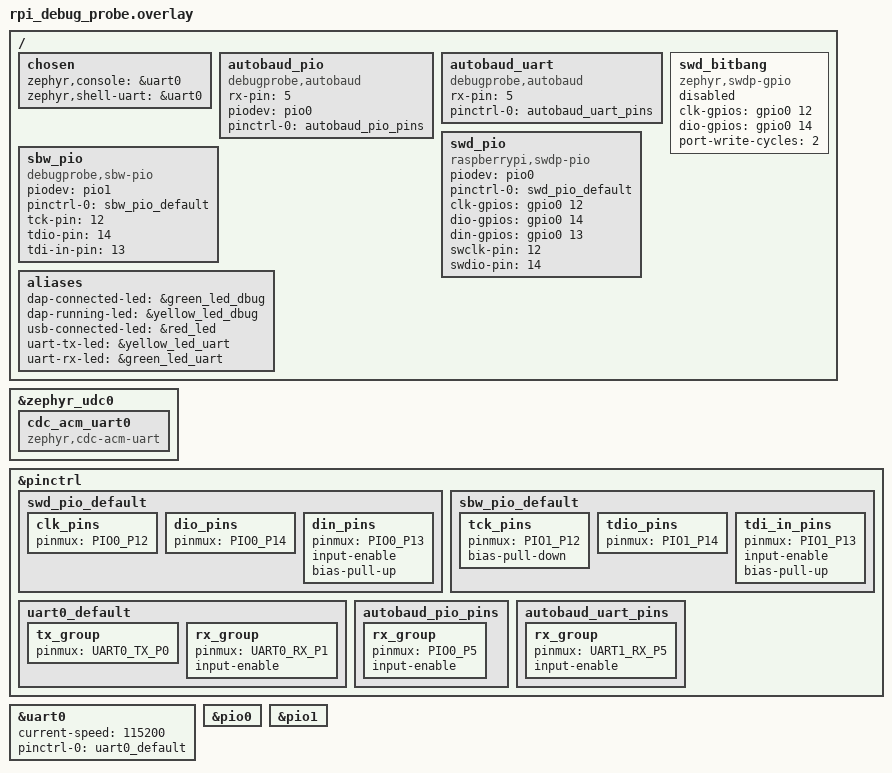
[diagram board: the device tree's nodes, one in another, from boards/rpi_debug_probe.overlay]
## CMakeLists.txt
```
cmake_minimum_required(VERSION 3.20.0)

# Register this repo as a Zephyr module (see zephyr/module.yml) so the
# out-of-tree PIO drivers in drivers/ (dp_pio and sbw_pio) are processed during Zephyr's
# module loop. That runs before Zephyr captures ZEPHYR_LIBS and builds the
# whole-archive link group; an app-local add_subdirectory() would register the
# driver too late, so their DEVICE_DT_INST_DEFINE device objects would be dropped
# and DEVICE_DT_GET(swd_pio) would fail to link. Must precede find_package().
list(APPEND EXTRA_ZEPHYR_MODULES ${CMAKE_CURRENT_SOURCE_DIR})

find_package(Zephyr REQUIRED HINTS $ENV{ZEPHYR_BASE})
project(debugprobe_zephyr LANGUAGES C CXX)

add_subdirectory(lib/dap)

target_sources(app PRIVATE
  src/main.cpp
  src/usb/usb_device.cpp
  src/usb/dap_class.cpp
  src/usb/msosv2.cpp
  src/dap/dap_backend.cpp
  src/leds.cpp
  src/pin_owner.cpp
  src/uart_bridge.cpp
  src/autobaud/autobaud.cpp
  src/autobaud/estimator.cpp
)

# The swdp_api adapter (and its C shim over the non-C++-clean swdp.h) is only
# needed for the real SWD backends; the NULL bring-up build excludes it.
if(NOT CONFIG_PROBE_SWD_NULL)
  target_sources(app PRIVATE
    src/dap/swdp_driver.cpp
    src/dap/swdp_shim.c
  )
endif()

# MSP430 Spy-Bi-Wire programming (vendor command 0x90): glue between the PIO
# driver in drivers/sbw_pio/, lib/msp430 and the DAP engine.
if(CONFIG_PROBE_MSP430_SBW)
  add_subdirectory(lib/msp430)
  target_sources(app PRIVATE
    src/msp430/pio_sbw_port.cpp
    src/msp430/msp430_backend.cpp
  )
  target_include_directories(app PRIVATE drivers/sbw_pio)
  target_link_libraries(app PRIVATE msp430)
endif()

target_include_directories(app PRIVATE src)
# The autobaud module (src/autobaud/autobaud.cpp) includes the generated
# autobaud_pio.h (PIO opcodes), which lives alongside the out-of-tree PIO
# driver in drivers/dp_pio/.
target_include_directories(app PRIVATE drivers/dp_pio)
target_link_libraries(app PRIVATE dap)
```

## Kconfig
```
mainmenu "debugprobe-zephyr"

config PROBE_PRODUCT_STRING
	string "USB product string"
	default "Debug Probe (CMSIS-DAP)" if BOARD_RPI_DEBUG_PROBE
	default "Debugprobe on Pico (CMSIS-DAP)" if BOARD_RPI_PICO || BOARD_RPI_PICO2
	default "Debugprobe (CMSIS-DAP)"

choice PROBE_SWD_BACKEND
	prompt "SWD driver backend"
	default PROBE_SWD_BITBANG
	help
	  Which SWD port driver backs the DAP engine.

config PROBE_SWD_NULL
	bool "Null (no SWD; bring-up only)"

config PROBE_SWD_BITBANG
	bool "Zephyr GPIO bitbang (zephyr,swdp-gpio)"

config PROBE_SWD_PIO
	bool "PIO-accelerated (raspberrypi,swdp-pio)"

endchoice

config PROBE_MSP430_SBW
	bool "MSP430 Spy-Bi-Wire programming and debugging (vendor command 0x90)"
	default y
	depends on PROBE_SWD_PIO && PIO_RPI_PICO && DT_HAS_DEBUGPROBE_SBW_PIO_ENABLED
	select SBW_PIO
	help
	  Program and debug MSP430 CPUXv2 flash devices (MSP430F5529) over
	  Spy-Bi-Wire, using the SWD pins. Adds a CMSIS-DAP vendor command; the
	  USB descriptors do not change. See docs/MSP430_SBW.md and
	  docs/MSP430_DEBUG.md.

# The SBW vendor command runs on the USB device thread and nests deeper than
# the SWD path (engine -> Session -> Debugger -> Cpuxv2/SbwTap -> port -> PIO
# driver). Zephyr's default of 1024 bytes leaves no margin for it. Static worst
# case of the debug paths, measured with -fstack-usage and the call graph on
# 2026-11-13: 1312 of 2048 bytes on the RP2040 boards (rpi_pico2: 1164), so
# 2048 is kept.
config USBD_THREAD_STACK_SIZE
	default 2048 if PROBE_MSP430_SBW

# The out-of-tree PIO driver Kconfigs (drivers/Kconfig, which pulls in dp_pio
# and sbw_pio) are sourced via the Zephyr module mechanism (zephyr/module.yml
# -> build.kconfig), not rsource'd here, so they are registered alongside the
# drivers' CMakeLists in the module loop. Sourcing them both ways would
# redefine SWDP_PIO.

source "Kconfig.zephyr"
```

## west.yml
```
manifest:
  remotes:
    - name: zephyrproject-rtos
      url-base: https://github.com/zephyrproject-rtos

  projects:
    - name: zephyr
      remote: zephyrproject-rtos
      revision: v4.4.0
      import:
        name-allowlist:
          - cmsis_6
          - hal_rpi_pico

  self:
    path: debugprobe-zephyr
```

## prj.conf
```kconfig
CONFIG_CPP=y
CONFIG_STD_CPP20=y
# GLIBCXX_LIBCPP (full libstdc++) depends on NEWLIB_LIBC || PICOLIBC;
# the gnuarmemb toolchain only provides newlib, so select it explicitly.
CONFIG_GLIBCXX_LIBCPP=y
CONFIG_NEWLIB_LIBC=y
CONFIG_LOG=y
CONFIG_USB_DEVICE_STACK_NEXT=y
CONFIG_USBD_CDC_ACM_CLASS=y
CONFIG_SERIAL=y
CONFIG_UART_LINE_CTRL=y
# CDC-ACM <-> target uart1 bridge is now a custom C++ UartBridge
# (src/uart_bridge.cpp), replacing the closed zephyr,uart-bridge so phase 4b
# can tap byte flow (activity LEDs) and intercept MAGIC_BAUD (autobaud). The
# bridge is interrupt-driven and ring-buffered, so it needs these explicitly
# (UART_INTERRUPT_DRIVEN was previously auto-selected by UART_BRIDGE):
CONFIG_UART_INTERRUPT_DRIVEN=y
CONFIG_RING_BUFFER=y
# Autobaud (src/autobaud/autobaud.cpp) uses a k_event to start/stop its
# capture thread, and uart_configure() to apply the detected baud at runtime.
CONFIG_EVENTS=y
CONFIG_UART_USE_RUNTIME_CONFIGURE=y
CONFIG_HWINFO=y
CONFIG_GPIO=y
CONFIG_DP_DRIVER=y
# Default SWD backend: PIO-accelerated (raspberrypi,swdp-pio). Flips the
# Kconfig choice default (BITBANG). The overlays default swd_pio=okay /
# swd_bitbang=disabled to match; switching to bitbang requires flipping both.
CONFIG_PROBE_SWD_PIO=y
# SWD block DMA (drivers/dp_pio): Zephyr DMA controller, not the raw SDK.
CONFIG_DMA=y
CONFIG_DMA_RPI_PICO=y
```

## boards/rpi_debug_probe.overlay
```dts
#include <zephyr/dt-bindings/pinctrl/rpi-pico-rp2040-pinctrl.h>

&zephyr_udc0 {
	cdc_acm_uart0: cdc_acm_uart0 {
		compatible = "zephyr,cdc-acm-uart";
	};
};

/* Route the Debug Probe's PIO SWD pins to PIO0 (the Zephyr way, via pinctrl).
 * SWCLK=GP12 (output), SWDIO=GP14 (output only -- the probe has a separate
 * input), SWDI=GP13 (the read pin: input-enable + pull-up).
 */
&pinctrl {
	swd_pio_default: swd_pio_default {
		clk_pins {
			pinmux = <PIO0_P12>;
		};
		dio_pins {
			pinmux = <PIO0_P14>;
		};
		din_pins {
			pinmux = <PIO0_P13>;
			input-enable;
			bias-pull-up;
		};
	};

	/* MSP430 Spy-Bi-Wire on the SWD pins, routed to PIO1: SBWTCK=GP12,
	 * SBWTDIO output=GP14, SBWTDIO input=GP13. */
	sbw_pio_default: sbw_pio_default {
		tck_pins {
			pinmux = <PIO1_P12>;
			bias-pull-down;
		};
		tdio_pins {
			pinmux = <PIO1_P14>;
		};
		tdi_in_pins {
			pinmux = <PIO1_P13>;
			input-enable;
			bias-pull-up;
		};
	};

	/* Console UART (uart0): TX=GP0, RX=GP1. The board defaults the console
	 * to uart1, but uart1 is the bridge target here, so the console moves to
	 * uart0 (chosen below) and needs its own pinctrl (the board DTS only
	 * defines uart1_default).
	 */
	uart0_default: uart0_default {
		tx_group {
			pinmux = <UART0_TX_P0>;
		};
		rx_group {
			pinmux = <UART0_RX_P1>;
			input-enable;
		};
	};

	/* Autobaud pin-handoff states for uart1 RX (GP5, same as the Picos). Two
	 * single-state dev-configs (the robust two-node approach): while
	 * measuring, route GP5 to PIO0 so the frequency-counter SM sees the
	 * edges; on stop, route it back to UART1 so the bridge's UART RX works
	 * again. Both keep input-enable so the pad samples the incoming line. */
	autobaud_pio_pins: autobaud_pio_pins {
		rx_group {
			pinmux = <PIO0_P5>;
			input-enable;
		};
	};
	autobaud_uart_pins: autobaud_uart_pins {
		rx_group {
			pinmux = <UART1_RX_P5>;
			input-enable;
		};
	};
};

/* Move the console/shell off uart1 (the board DTS chose uart1) so the bridge
 * owns uart1 exclusively, and enable uart0 as the console UART.
 */
&uart0 {
	status = "okay";
	current-speed = <115200>;
	pinctrl-0 = <&uart0_default>;
	pinctrl-names = "default";
};

/* Enable PIO0 so the misc PIO HAL (PIO_RPI_PICO) builds, which the dp_pio
 * driver compiles against, and so the raspberrypi,swdp-pio instance can run.
 */
&pio0 {
	status = "okay";
};

/* PIO1 hosts the SBW program: PIO0's instruction memory is shared by the SWD
 * and autobaud programs. */
&pio1 {
	status = "okay";
};

/ {
	/* uart1 is already enabled (status=okay, uart1_default pinctrl) in the
	 * board DTS and was the console -- move the console/shell to uart0 so the
	 * CDC-ACM <-> uart1 bridge owns uart1.
	 */
	chosen {
		zephyr,console = &uart0;
		zephyr,shell-uart = &uart0;
	};

	/* CDC-ACM (USB) <-> uart1 (target) bridge is now a custom C++ UartBridge
	 * (src/uart_bridge.cpp) that binds cdc_acm_uart0 and uart1 (already okay
	 * in the board DTS) directly, so there is no zephyr,uart-bridge DT node
	 * here anymore.
	 */

	/* Autobaud pin-handoff anchors (compatible debugprobe,autobaud). The
	 * autobaud module (src/autobaud/autobaud.cpp) references these two nodes
	 * via DT_NODELABEL to obtain the two single-state pinctrl dev-configs:
	 * autobaud_pio routes uart1 RX (GP5) to PIO0 while measuring;
	 * autobaud_uart routes it back to UART1 on stop. rx-pin carries the RX
	 * GPIO number for the PIO SM config. No driver binds these; the binding
	 * exists only for the pinctrl + rx-pin DT codegen. */
	autobaud_pio: autobaud_pio {
		compatible = "debugprobe,autobaud";
		rx-pin = <5>;
		piodev = <&pio0>;
		pinctrl-0 = <&autobaud_pio_pins>;
		pinctrl-names = "default";
	};
	autobaud_uart: autobaud_uart {
		compatible = "debugprobe,autobaud";
		rx-pin = <5>;
		pinctrl-0 = <&autobaud_uart_pins>;
		pinctrl-names = "default";
	};

	/* The real Raspberry Pi Debug Probe (PROBE_IO_SWDI, per
	 * board_debug_probe_config.h): SWCLK=GP12, SWDIO output=GP14, separate
	 * SWDI input=GP13, no OEn, no nRESET pin. The PIO node carries a
	 * din-gpios for the separate input (driver use_swdi axis, still
	 * probe.pio). Exactly one backend is enabled: PIO is the default
	 * (CONFIG_PROBE_SWD_PIO=y); to use bitbang, flip both the Kconfig
	 * choice and these two status values.
	 */
	swd_bitbang: swd_bitbang {
		compatible = "zephyr,swdp-gpio";
		clk-gpios = <&gpio0 12 GPIO_ACTIVE_HIGH>;
		dio-gpios = <&gpio0 14 (GPIO_PULL_UP | GPIO_ACTIVE_HIGH)>;
		port-write-cycles = <2>;
		status = "disabled";
	};

	swd_pio: swd_pio {
		compatible = "raspberrypi,swdp-pio";
		piodev = <&pio0>;
		pinctrl-0 = <&swd_pio_default>;
		pinctrl-names = "default";
		clk-gpios = <&gpio0 12 GPIO_ACTIVE_HIGH>;
		dio-gpios = <&gpio0 14 GPIO_ACTIVE_HIGH>;
		din-gpios = <&gpio0 13 GPIO_ACTIVE_HIGH>;
		swclk-pin = <12>;
		swdio-pin = <14>;
		status = "okay";
	};

	sbw_pio: sbw_pio {
		compatible = "debugprobe,sbw-pio";
		piodev = <&pio1>;
		pinctrl-0 = <&sbw_pio_default>;
		pinctrl-names = "default";
		tck-pin = <12>;
		tdio-pin = <14>;
		tdi-in-pin = <13>;
		status = "okay";
	};

	/* Status LEDs (gpio-leds nodes in the board DTS), matching the original
	 * debug-probe mapping: DAP_CONNECTED=GP15 (green_led_dbug),
	 * DAP_RUNNING=GP16 (yellow_led_dbug), USB=GP2 (red_led).
	 */
	aliases {
		dap-connected-led = &green_led_dbug;
		dap-running-led = &yellow_led_dbug;
		usb-connected-led = &red_led;
		uart-tx-led = &yellow_led_uart;
		uart-rx-led = &green_led_uart;
	};
};
```

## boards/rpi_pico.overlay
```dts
#include <zephyr/dt-bindings/pinctrl/rpi-pico-rp2040-pinctrl.h>

&zephyr_udc0 {
	cdc_acm_uart0: cdc_acm_uart0 {
		compatible = "zephyr,cdc-acm-uart";
	};
};

/* Route the PIO SWD pins to the PIO0 function (the Zephyr way, via pinctrl).
 * SWCLK=GP2 (PIO output), SWDIO=GP3 (shared in/out: input-enable so `in pins`
 * can sample it, pull-up for the idle-high SWD bus).
 */
&pinctrl {
	swd_pio_default: swd_pio_default {
		clk_pins {
			pinmux = <PIO0_P2>;
		};
		dio_pins {
			pinmux = <PIO0_P3>;
			input-enable;
			bias-pull-up;
		};
	};

	/* MSP430 Spy-Bi-Wire on the SWD pins, routed to PIO1: SBWTCK=GP2 (target
	 * TEST), SBWTDIO=GP3 (target RST). The pulls define the idle state:
	 * pull-up on SBWTDIO so the probe does not fight the target's RST
	 * pull-up, pull-down on SBWTCK (TEST low = SBW logic off). */
	sbw_pio_default: sbw_pio_default {
		tck_pins {
			pinmux = <PIO1_P2>;
			bias-pull-down;
		};
		tdio_pins {
			pinmux = <PIO1_P3>;
			input-enable;
			bias-pull-up;
		};
	};

	/* Target UART (uart1): TX=GP4, RX=GP5 -- the CDC-ACM bridge endpoint. */
	uart1_default: uart1_default {
		tx_group {
			pinmux = <UART1_TX_P4>;
		};
		rx_group {
			pinmux = <UART1_RX_P5>;
			input-enable;
		};
	};

	/* Autobaud pin-handoff states for uart1 RX (GP5). Two single-state
	 * dev-configs (the robust two-node approach): while measuring, route GP5
	 * to PIO0 so the frequency-counter SM sees the edges; on stop, route it
	 * back to UART1 so the bridge's UART RX works again. Both keep
	 * input-enable so the pad samples the incoming line. */
	autobaud_pio_pins: autobaud_pio_pins {
		rx_group {
			pinmux = <PIO0_P5>;
			input-enable;
		};
	};
	autobaud_uart_pins: autobaud_uart_pins {
		rx_group {
			pinmux = <UART1_RX_P5>;
			input-enable;
		};
	};
};

/* Enable uart1 as the bridge's hardware side. The board defaults the console
 * to uart0 (GP0/GP1), so uart1 is free to be the target UART.
 */
&uart1 {
	status = "okay";
	current-speed = <115200>;
	pinctrl-0 = <&uart1_default>;
	pinctrl-names = "default";
};

/* Enable PIO0 so the misc PIO HAL (PIO_RPI_PICO) builds, which the dp_pio
 * driver compiles against, and so the raspberrypi,swdp-pio instance can run.
 */
&pio0 {
	status = "okay";
};

/* PIO1 hosts the SBW program: PIO0's instruction memory is shared by the SWD
 * and autobaud programs. */
&pio1 {
	status = "okay";
};

/ {
	/* CDC-ACM (USB) <-> uart1 (target) bridge is now a custom C++ UartBridge
	 * (src/uart_bridge.cpp) that binds cdc_acm_uart0 and uart1 directly, so
	 * there is no zephyr,uart-bridge DT node here anymore.
	 */

	/* Autobaud pin-handoff anchors (compatible debugprobe,autobaud). The
	 * autobaud module (src/autobaud/autobaud.cpp) references these two nodes
	 * via DT_NODELABEL to obtain the two single-state pinctrl dev-configs:
	 * autobaud_pio routes uart1 RX (GP5) to PIO0 while measuring;
	 * autobaud_uart routes it back to UART1 on stop. rx-pin carries the RX
	 * GPIO number for the PIO SM config. No driver binds these; the binding
	 * exists only for the pinctrl + rx-pin DT codegen. */
	autobaud_pio: autobaud_pio {
		compatible = "debugprobe,autobaud";
		rx-pin = <5>;
		piodev = <&pio0>;
		pinctrl-0 = <&autobaud_pio_pins>;
		pinctrl-names = "default";
	};
	autobaud_uart: autobaud_uart {
		compatible = "debugprobe,autobaud";
		rx-pin = <5>;
		pinctrl-0 = <&autobaud_uart_pins>;
		pinctrl-names = "default";
	};

	/* Two SWD backends share these pins (GP2=SWCLK, GP3=shared SWDIO,
	 * GP1=nRESET). Exactly one is enabled at a time: the PIO node is the
	 * default (CONFIG_PROBE_SWD_PIO=y); to use bitbang, flip both the
	 * Kconfig choice and these two status values.
	 */
	swd_bitbang: swd_bitbang {
		compatible = "zephyr,swdp-gpio";
		clk-gpios = <&gpio0 2 GPIO_ACTIVE_HIGH>;
		dio-gpios = <&gpio0 3 (GPIO_PULL_UP | GPIO_ACTIVE_HIGH)>;
		reset-gpios = <&gpio0 1 GPIO_ACTIVE_LOW>;
		port-write-cycles = <2>;
		status = "disabled";
	};

	swd_pio: swd_pio {
		compatible = "raspberrypi,swdp-pio";
		piodev = <&pio0>;
		pinctrl-0 = <&swd_pio_default>;
		pinctrl-names = "default";
		clk-gpios = <&gpio0 2 GPIO_ACTIVE_HIGH>;
		dio-gpios = <&gpio0 3 (GPIO_PULL_UP | GPIO_ACTIVE_HIGH)>;
		reset-gpios = <&gpio0 1 GPIO_ACTIVE_LOW>;
		swclk-pin = <2>;
		swdio-pin = <3>;
		status = "okay";
	};

	sbw_pio: sbw_pio {
		compatible = "debugprobe,sbw-pio";
		piodev = <&pio1>;
		pinctrl-0 = <&sbw_pio_default>;
		pinctrl-names = "default";
		tck-pin = <2>;
		tdio-pin = <3>;
		status = "okay";
	};

	/* Single onboard LED (led0 = GP25): use it as the USB-connected
	 * indicator. There are no separate DAP connect/run LEDs on this board,
	 * so those aliases are absent and their helpers no-op.
	 */
	aliases {
		usb-connected-led = &led0;
	};
};
```

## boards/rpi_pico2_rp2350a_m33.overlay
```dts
#include <zephyr/dt-bindings/pinctrl/rpi-pico-rp2350a-pinctrl.h>

&zephyr_udc0 {
	cdc_acm_uart0: cdc_acm_uart0 {
		compatible = "zephyr,cdc-acm-uart";
	};
};

/* Route the PIO SWD pins to the PIO0 function (the Zephyr way, via pinctrl).
 * SWCLK=GP2 (PIO output), SWDIO=GP3 (shared in/out: input-enable + pull-up).
 */
&pinctrl {
	swd_pio_default: swd_pio_default {
		clk_pins {
			pinmux = <PIO0_P2>;
		};
		dio_pins {
			pinmux = <PIO0_P3>;
			input-enable;
			bias-pull-up;
		};
	};

	/* MSP430 Spy-Bi-Wire on the SWD pins, routed to PIO1: SBWTCK=GP2 (target
	 * TEST), SBWTDIO=GP3 (target RST). The pulls define the idle state:
	 * pull-up on SBWTDIO so the probe does not fight the target's RST
	 * pull-up, pull-down on SBWTCK (TEST low = SBW logic off). */
	sbw_pio_default: sbw_pio_default {
		tck_pins {
			pinmux = <PIO1_P2>;
			bias-pull-down;
		};
		tdio_pins {
			pinmux = <PIO1_P3>;
			input-enable;
			bias-pull-up;
		};
	};

	/* Target UART (uart1): TX=GP4, RX=GP5 -- the CDC-ACM bridge endpoint. */
	uart1_default: uart1_default {
		tx_group {
			pinmux = <UART1_TX_P4>;
		};
		rx_group {
			pinmux = <UART1_RX_P5>;
			input-enable;
		};
	};

	/* Autobaud pin-handoff states for uart1 RX (GP5). Two single-state
	 * dev-configs (the robust two-node approach): while measuring, route GP5
	 * to PIO0 so the frequency-counter SM sees the edges; on stop, route it
	 * back to UART1 so the bridge's UART RX works again. Both keep
	 * input-enable so the pad samples the incoming line. */
	autobaud_pio_pins: autobaud_pio_pins {
		rx_group {
			pinmux = <PIO0_P5>;
			input-enable;
		};
	};
	autobaud_uart_pins: autobaud_uart_pins {
		rx_group {
			pinmux = <UART1_RX_P5>;
			input-enable;
		};
	};
};

/* Enable uart1 as the bridge's hardware side. The board defaults the console
 * to uart0 (GP0/GP1), so uart1 is free to be the target UART.
 */
&uart1 {
	status = "okay";
	current-speed = <115200>;
	pinctrl-0 = <&uart1_default>;
	pinctrl-names = "default";
};

/* Enable PIO0 so the misc PIO HAL (PIO_RPI_PICO) builds, which the dp_pio
 * driver compiles against, and so the raspberrypi,swdp-pio instance can run.
 */
&pio0 {
	status = "okay";
};

/* PIO1 hosts the SBW program: PIO0's instruction memory is shared by the SWD
 * and autobaud programs. */
&pio1 {
	status = "okay";
};

/ {
	/* CDC-ACM (USB) <-> uart1 (target) bridge is now a custom C++ UartBridge
	 * (src/uart_bridge.cpp) that binds cdc_acm_uart0 and uart1 directly, so
	 * there is no zephyr,uart-bridge DT node here anymore.
	 */

	/* Autobaud pin-handoff anchors (compatible debugprobe,autobaud). The
	 * autobaud module (src/autobaud/autobaud.cpp) references these two nodes
	 * via DT_NODELABEL to obtain the two single-state pinctrl dev-configs:
	 * autobaud_pio routes uart1 RX (GP5) to PIO0 while measuring;
	 * autobaud_uart routes it back to UART1 on stop. rx-pin carries the RX
	 * GPIO number for the PIO SM config. No driver binds these; the binding
	 * exists only for the pinctrl + rx-pin DT codegen. */
	autobaud_pio: autobaud_pio {
		compatible = "debugprobe,autobaud";
		rx-pin = <5>;
		piodev = <&pio0>;
		pinctrl-0 = <&autobaud_pio_pins>;
		pinctrl-names = "default";
	};
	autobaud_uart: autobaud_uart {
		compatible = "debugprobe,autobaud";
		rx-pin = <5>;
		pinctrl-0 = <&autobaud_uart_pins>;
		pinctrl-names = "default";
	};

	/* Two SWD backends share these pins (GP2=SWCLK, GP3=shared SWDIO,
	 * GP1=nRESET). Exactly one is enabled at a time: the PIO node is the
	 * default (CONFIG_PROBE_SWD_PIO=y); to use bitbang, flip both the
	 * Kconfig choice and these two status values.
	 */
	swd_bitbang: swd_bitbang {
		compatible = "zephyr,swdp-gpio";
		clk-gpios = <&gpio0 2 GPIO_ACTIVE_HIGH>;
		dio-gpios = <&gpio0 3 (GPIO_PULL_UP | GPIO_ACTIVE_HIGH)>;
		reset-gpios = <&gpio0 1 GPIO_ACTIVE_LOW>;
		port-write-cycles = <2>;
		status = "disabled";
	};

	swd_pio: swd_pio {
		compatible = "raspberrypi,swdp-pio";
		piodev = <&pio0>;
		pinctrl-0 = <&swd_pio_default>;
		pinctrl-names = "default";
		clk-gpios = <&gpio0 2 GPIO_ACTIVE_HIGH>;
		dio-gpios = <&gpio0 3 (GPIO_PULL_UP | GPIO_ACTIVE_HIGH)>;
		reset-gpios = <&gpio0 1 GPIO_ACTIVE_LOW>;
		swclk-pin = <2>;
		swdio-pin = <3>;
		status = "okay";
	};

	sbw_pio: sbw_pio {
		compatible = "debugprobe,sbw-pio";
		piodev = <&pio1>;
		pinctrl-0 = <&sbw_pio_default>;
		pinctrl-names = "default";
		tck-pin = <2>;
		tdio-pin = <3>;
		status = "okay";
	};

	/* Single onboard LED (led0): use it as the USB-connected indicator.
	 * No separate DAP connect/run LEDs on this board, so those aliases are
	 * absent and their helpers no-op.
	 */
	aliases {
		usb-connected-led = &led0;
	};
};
```

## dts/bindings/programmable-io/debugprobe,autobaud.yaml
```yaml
# Copyright The Zephyr Project Contributors
# SPDX-License-Identifier: Apache-2.0

description: |
  Autobaud pin-handoff anchor. Carries a single pinctrl state used by the
  autobaud module (src/autobaud/autobaud.cpp) to route uart1's RX pin either to
  PIO0 (while the frequency counter measures) or back to UART1 (on stop). No
  driver binds these nodes; the binding exists only so devicetree emits the
  pinctrl-0/pinctrl-names metadata and the rx-pin property.

compatible: "debugprobe,autobaud"

# pinctrl-device.yaml provides pinctrl-0/pinctrl-names codegen (the same include
# raspberrypi,swdp-pio uses to route pins to the PIO funcsel).
include: [base.yaml, pinctrl-device.yaml]

properties:
  rx-pin:
    type: int
    required: true
    description: uart1 RX GPIO number, passed to the PIO SM as in_pins/jmp_pin.

  piodev:
    type: phandle
    description: |
      The PIO instance (pio0) the autobaud frequency counter runs on. A phandle
      (not DT_NODELABEL(pio0)) so the reference survives the pico-sdk
      hardware/pio.h `#define pio0 pio0_hw` token collision.
```

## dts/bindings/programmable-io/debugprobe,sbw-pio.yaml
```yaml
# SPDX-License-Identifier: MIT

description: |
  PIO Spy-Bi-Wire transport for MSP430 targets. Shares the SWD pins: SBWTCK on
  the SWCLK pin (target TEST), SBWTDIO on the SWDIO pin (target RST). The
  pinctrl state routes the pins to this node's PIO instance and sets the idle
  pulls (pull-up on SBWTDIO, pull-down on SBWTCK).

compatible: "debugprobe,sbw-pio"

include: [base.yaml, pinctrl-device.yaml]

properties:
  piodev:
    type: phandle
    required: true
    description: |
      The PIO instance that runs the SBW program. A phandle (not a node label
      in C) because hardware/pio.h defines pio0/pio1 as macros.

  tck-pin:
    type: int
    required: true
    description: SBWTCK GPIO number (PIO side-set base).

  tdio-pin:
    type: int
    required: true
    description: SBWTDIO GPIO number (PIO out/set base, and input base by default).

  tdi-in-pin:
    type: int
    description: Separate SBWTDIO input GPIO, for boards with split in/out pins.
```

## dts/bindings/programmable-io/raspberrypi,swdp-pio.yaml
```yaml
# Copyright The Zephyr Project Contributors
# SPDX-License-Identifier: Apache-2.0

description: Raspberry Pi PIO-accelerated SWD port

compatible: "raspberrypi,swdp-pio"

# base.yaml: status/compatible/etc. pinctrl-device.yaml: pinctrl-0/pinctrl-names,
# used (the Zephyr way, as in raspberrypi,pico-uart-pio) to route SWCLK/SWDIO/SWDI
# to the PIO funcsel. swclk-pin/swdio-pin still give the PIO SM its side-set/out/in
# pin numbers; nRESET goes through reset-gpios.
include: [base.yaml, pinctrl-device.yaml]

properties:
  piodev:
    type: phandle
    required: true
    description: The PIO instance (pio0/pio1) hosting the SWD program.

  clk-gpios:
    type: phandle-array
    required: true
    description: SWCLK pin.

  dio-gpios:
    type: phandle-array
    required: true
    description: SWDIO pin (shared in/out on Pico; output on buffered probe).

  din-gpios:
    type: phandle-array
    description: Separate SWDIO input pin (buffered Debug Probe only).

  oen-gpios:
    type: phandle-array
    description: Output-enable pin for the level shifter (buffered probe only).

  reset-gpios:
    type: phandle-array
    description: Target nRESET pin (open-drain emulation).

  swclk-pin:
    type: int
    required: true
    description: SWCLK GPIO number (PIO side-set base).

  swdio-pin:
    type: int
    required: true
    description: SWDIO GPIO number (PIO out/in base).
```

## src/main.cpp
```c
#include <zephyr/kernel.h>
#include <zephyr/logging/log.h>

#include <array>
#include <span>

#include "usb/usb_device.hpp"
#include "uart_bridge.hpp"

#if defined(CONFIG_PROBE_MSP430_SBW)
#include "msp430/msp430_backend.hpp"
#endif

LOG_MODULE_REGISTER(main, LOG_LEVEL_INF);

namespace {

/* C++20 smoke check: if concepts + std::span compile, the toolchain and
 * Kconfig selections are correct.
 */
template <typename T>
concept ByteBuffer = requires(T t) {
	{ t.size() } -> std::convertible_to<size_t>;
	{ t.data() };
};

static_assert(ByteBuffer<std::array<uint8_t, 4>>);
static_assert(ByteBuffer<std::span<const uint8_t>>);

} // namespace

int main()
{
	LOG_INF("debugprobe-zephyr starting");

#if defined(CONFIG_PROBE_MSP430_SBW)
	/* MSP430 Spy-Bi-Wire: vendor command 0x90 on the DAP interface. */
	probe::msp430_backend::init();
#endif

	if (int err = probe::usb::init(); err != 0) {
		LOG_ERR("USB init failed: %d", err);
		return err;
	}

	/* Wire the CDC-ACM <-> uart1 data path (custom interrupt-driven bridge,
	 * replacing zephyr,uart-bridge). */
	probe::uart_bridge_init();

	/* USB runs on the usbd thread + controller IRQs; nothing for main to do. */
	return 0;
}
```

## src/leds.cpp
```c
#include "leds.hpp"

#include <zephyr/devicetree.h>
#include <zephyr/drivers/gpio.h>
#include <zephyr/kernel.h>

namespace probe {

namespace {

/* A LED is present only if the alias resolves to a gpios property. Each entry
 * is compiled out to an empty spec ({0}) when its alias is absent, and the
 * helpers no-op on a null port. */
#define LED_SPEC(alias) \
	GPIO_DT_SPEC_GET_OR(DT_ALIAS(alias), gpios, {0})

const struct gpio_dt_spec dap_connected = LED_SPEC(dap_connected_led);
const struct gpio_dt_spec dap_running = LED_SPEC(dap_running_led);
const struct gpio_dt_spec usb_connected = LED_SPEC(usb_connected_led);
const struct gpio_dt_spec uart_tx_led = LED_SPEC(uart_tx_led);
const struct gpio_dt_spec uart_rx_led = LED_SPEC(uart_rx_led);

void led_configure(const struct gpio_dt_spec *led)
{
	if (led->port != nullptr && gpio_is_ready_dt(led)) {
		gpio_pin_configure_dt(led, GPIO_OUTPUT_INACTIVE);
	}
}

void led_set(const struct gpio_dt_spec *led, bool on)
{
	if (led->port != nullptr && gpio_is_ready_dt(led)) {
		gpio_pin_set_dt(led, on ? 1 : 0);
	}
}

void tx_off(struct k_timer *) { led_set(&uart_tx_led, false); }
void rx_off(struct k_timer *) { led_set(&uart_rx_led, false); }
K_TIMER_DEFINE(tx_timer, tx_off, nullptr);
K_TIMER_DEFINE(rx_timer, rx_off, nullptr);
constexpr k_timeout_t kDebounce = K_MSEC(40);

struct LedInit {
	LedInit()
	{
		led_configure(&dap_connected);
		led_configure(&dap_running);
		led_configure(&usb_connected);
		led_configure(&uart_tx_led);
		led_configure(&uart_rx_led);
	}
};
const LedInit led_init;

} // namespace

void LedHostStatus::connected(bool on)
{
	led_set(&dap_connected, on);
}

void LedHostStatus::running(bool on)
{
	led_set(&dap_running, on);
}

void leds_usb_connected(bool on)
{
	led_set(&usb_connected, on);
}

void leds_uart_tx_activity()
{
	led_set(&uart_tx_led, true);
	k_timer_start(&tx_timer, kDebounce, K_NO_WAIT);
}

void leds_uart_rx_activity()
{
	led_set(&uart_rx_led, true);
	k_timer_start(&rx_timer, kDebounce, K_NO_WAIT);
}

} // namespace probe
```

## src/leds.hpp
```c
#pragma once
/* Drives the probe's status LEDs from the DAP engine's HostStatus.
 * Uses devicetree aliases (dap-connected-led, dap-running-led,
 * usb-connected-led); any alias that is absent on a board is a no-op.
 */
#include "dap/interfaces.hpp"

namespace probe {

class LedHostStatus final : public dap::HostStatus {
public:
	void connected(bool on) override;   /* DAP target connected (HostStatus type 0) */
	void running(bool on) override;     /* DAP target running (HostStatus type 1) */
};

/* Turn the USB-connected indicator on once the USB device is configured. */
void leds_usb_connected(bool on);

/* UART bridge activity: call on each byte; the LED lights and auto-clears
 * ~40 ms after the last byte (debounce). No-op if the alias is absent. */
void leds_uart_tx_activity();
void leds_uart_rx_activity();

} // namespace probe
```

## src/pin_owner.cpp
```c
#include "pin_owner.hpp"

namespace probe::pin_owner {

namespace {

enum class Owner { None, Swd, Sbw };

Owner g_owner = Owner::None;
void (*g_force_close)() = nullptr;
void (*g_idle)() = nullptr;

} // namespace

void swd_connect()
{
	if (g_owner == Owner::Sbw && g_force_close != nullptr) {
		g_force_close(); /* releases the pins through sbw_release() */
	}
	g_owner = Owner::Swd;
}

void swd_disconnect()
{
	if (g_owner == Owner::Swd) {
		g_owner = Owner::None;
		if (g_idle != nullptr) {
			g_idle(); /* the SWD driver leaves the pins driven */
		}
	}
}

bool sbw_claim()
{
	if (g_owner == Owner::Swd) {
		return false;
	}
	g_owner = Owner::Sbw;
	return true;
}

void sbw_release()
{
	if (g_owner == Owner::Sbw) {
		g_owner = Owner::None;
	}
}

bool sbw_owns()
{
	return g_owner == Owner::Sbw;
}

void set_sbw_force_close(void (*hook)())
{
	g_force_close = hook;
}

void set_idle_hook(void (*hook)())
{
	g_idle = hook;
}

} // namespace probe::pin_owner
```

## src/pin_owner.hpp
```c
#pragma once
/* Who drives the two debug pins: the SWD port (PIO0) or the SBW port (PIO1).
 * Pure C++ (host-tested). Every call comes from the DAP request thread, so
 * there is no locking.
 */
namespace probe::pin_owner {

/* SWD is taking the pins. An open SBW session is force-closed first, so a
 * crashed SBW tool cannot lock out an SWD debugger. */
void swd_connect();
void swd_disconnect();

/* SBW asks for the pins. Refused while SWD is connected. */
bool sbw_claim();
void sbw_release();
/* True while SBW holds the pins. */
bool sbw_owns();

/* Hook that closes an open SBW session; installed by the MSP430 backend. */
void set_sbw_force_close(void (*hook)());
/* Hook that returns the pins to their idle state (high-impedance, idle pulls)
 * after SWD lets go of them; installed by the MSP430 backend. */
void set_idle_hook(void (*hook)());

} // namespace probe::pin_owner
```

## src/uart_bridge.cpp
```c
#include "uart_bridge.hpp"
#include "leds.hpp"
#include "autobaud/autobaud.hpp"

#include <zephyr/drivers/uart.h>
#include <zephyr/sys/ring_buffer.h>
#include <zephyr/logging/log.h>

LOG_MODULE_REGISTER(uart_bridge, LOG_LEVEL_INF);

namespace probe {

namespace {

/* Modeled exactly on Zephyr's drivers/serial/uart_bridge.c: each device owns a
 * ring into which data received FROM that device is written; that ring is
 * drained out the PEER device's TX. The two-index `own`/peer scheme keeps the
 * two directions from crossing. Here the two devices are fixed (cdc_acm_uart0
 * and uart1) so the DT `peers`/`get_idx` machinery is replaced by direct
 * lookups, but the RX/TX/pause/resume mechanics are identical.
 */

constexpr size_t kRingSize = 256;
/* uart_bridge.c uses RING_BUF_SIZE/3; keep the same one-third threshold so the
 * pause/resume hysteresis behaves the same. */
constexpr size_t kFullThreshold = kRingSize / 3;

const struct device *const cdc_dev = DEVICE_DT_GET(DT_NODELABEL(cdc_acm_uart0));
const struct device *const uart_dev = DEVICE_DT_GET(DT_NODELABEL(uart1));

struct Peer {
	const struct device *dev;  /* the device this ring belongs to */
	const struct device *peer; /* where this ring's data is drained OUT */
	struct ring_buf rb;
	bool paused;               /* RX was disabled because the ring filled up */
	uint8_t buf[kRingSize];
};

/* g_cdc holds data received FROM the CDC, drained OUT to uart1.
 * g_uart holds data received FROM uart1, drained OUT to the CDC. */
Peer g_cdc;
Peer g_uart;

/* The ring OWNED by `dev` (where data read from `dev` is stored). */
Peer &own_ring(const struct device *dev)
{
	return (dev == cdc_dev) ? g_cdc : g_uart;
}

/* The ring whose data should be sent OUT through `dev` (the peer's own ring).
 * If `dev` is the CDC, that is the data received from uart1 (g_uart), and vice
 * versa. This mirrors uart_bridge.c's `peer[get_idx(dev, own=false)]`. */
Peer &out_ring(const struct device *dev)
{
	return (dev == cdc_dev) ? g_uart : g_cdc;
}

/* RX-ready on `dev`: read FROM `dev` into ITS OWN ring; enable the PEER's TX so
 * the data is flushed out the other side. Mirrors uart_bridge_handle_rx(). */
void handle_rx(const struct device *dev)
{
	Peer &self = own_ring(dev);

	if (ring_buf_space_get(&self.rb) < kFullThreshold) {
		/* Ring nearly full: stop reading this side until the peer drains
		 * it (resumed from handle_tx once space recovers). */
		uart_irq_rx_disable(dev);
		self.paused = true;
		return;
	}

	uint8_t *recv_buf = nullptr;
	uint32_t rb_len = ring_buf_put_claim(&self.rb, &recv_buf, kRingSize);
	if (rb_len == 0) {
		LOG_WRN("%s: ring_buf full", dev->name);
		return;
	}

	int recv_len = uart_fifo_read(dev, recv_buf, rb_len);
	if (recv_len < 0) {
		ring_buf_put_finish(&self.rb, 0);
		LOG_ERR("%s: rx error: %d", dev->name, recv_len);
		return;
	}

	if (ring_buf_put_finish(&self.rb, recv_len) < 0) {
		LOG_ERR("%s: ring_buf_put_finish error", dev->name);
		return;
	}

	/* Spurious RX-ready IRQs (e.g. CDC-ACM) can yield recv_len == 0; skip
	 * the LED blink and peer TX-enable when no bytes were actually read. */
	if (recv_len == 0) {
		return;
	}

	/* Activity LEDs: data read FROM the CDC (host→target) = TX; data read
	 * FROM uart1 (target→host) = RX. Mirrors original cdc_uart.c blink. */
	if (dev == cdc_dev) {
		probe::leds_uart_tx_activity();
	} else {
		probe::leds_uart_rx_activity();
	}

	uart_irq_tx_enable(self.peer);
}

/* TX-ready on `dev`: `dev` is a TX target, so drain the ring whose data should
 * go OUT through `dev` (the peer device's received-data ring) into `dev`'s
 * FIFO. If empty, disable `dev`'s TX. If the source side was paused on a full
 * ring and space has recovered, re-enable its RX. Mirrors
 * uart_bridge_handle_tx(). */
void handle_tx(const struct device *dev)
{
	Peer &src = out_ring(dev);

	uint8_t *send_buf = nullptr;
	uint32_t rb_len = ring_buf_get_claim(&src.rb, &send_buf, kRingSize);
	if (rb_len == 0) {
		uart_irq_tx_disable(dev);
		return;
	}

	int sent_len = uart_fifo_fill(dev, send_buf, rb_len);
	if (sent_len < 0) {
		ring_buf_get_finish(&src.rb, 0);
		LOG_ERR("%s: tx error: %d", dev->name, sent_len);
		return;
	}

	if (ring_buf_get_finish(&src.rb, sent_len) < 0) {
		LOG_ERR("%s: ring_buf_get_finish error", dev->name);
		return;
	}

	if (src.paused && ring_buf_space_get(&src.rb) > kFullThreshold) {
		/* Source ring drained enough: let it receive again. src.dev is
		 * the device that fills this ring (the peer of `dev`). */
		uart_irq_rx_enable(src.dev);
		src.paused = false;
	}
}

/* Drain RX of `dev` into its ring; push the peer's ring into `dev`'s TX.
 * Mirrors uart_bridge.c interrupt_handler. */
void isr(const struct device *dev, void *user_data)
{
	ARG_UNUSED(user_data);

	while (uart_irq_update(dev) && uart_irq_is_pending(dev)) {
		if (uart_irq_rx_ready(dev)) {
			handle_rx(dev);
		}
		if (uart_irq_tx_ready(dev)) {
			handle_tx(dev);
		}
	}
}

} // namespace

void uart_bridge_init()
{
	if (!device_is_ready(cdc_dev) || !device_is_ready(uart_dev)) {
		LOG_ERR("bridge devices not ready");
		return;
	}

	g_cdc.dev = cdc_dev;
	g_cdc.peer = uart_dev;
	g_cdc.paused = false;
	g_uart.dev = uart_dev;
	g_uart.peer = cdc_dev;
	g_uart.paused = false;

	ring_buf_init(&g_cdc.rb, kRingSize, g_cdc.buf);
	ring_buf_init(&g_uart.rb, kRingSize, g_uart.buf);

	uart_irq_callback_user_data_set(cdc_dev, isr, nullptr);
	uart_irq_callback_user_data_set(uart_dev, isr, nullptr);
	uart_irq_rx_enable(cdc_dev);
	uart_irq_rx_enable(uart_dev);
}

void uart_bridge_line_coding(const struct device *cdc)
{
	struct uart_config cfg;
	if (uart_config_get(cdc, &cfg) != 0) {
		return;
	}
	if (cfg.baudrate == probe::kMagicBaud) {
		/* MAGIC_BAUD is a host-side sentinel, not a real rate: start
		 * autobaud and do NOT push it to the target UART. */
		probe::autobaud_start();
		return;
	}
	/* A real baud cancels any running autobaud (it restores the RX pin). */
	probe::autobaud_stop();
	uart_configure(uart_dev, &cfg);
}

} // namespace probe
```

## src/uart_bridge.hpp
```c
#pragma once
/* CDC-ACM <-> hardware UART bridge (custom, replacing zephyr,uart-bridge),
 * so phase 4b can tap byte flow for activity LEDs and intercept the
 * MAGIC_BAUD line-coding to drive autobaud.
 */
#include <zephyr/device.h>

namespace probe {

/* Start the bridge between the CDC-ACM and the hardware UART (both Zephyr
 * uart devices). Call once at startup after the devices are ready. */
void uart_bridge_init();

/* Apply the CDC line coding to the hardware UART (called from the usbd
 * line-coding message). If the requested bit rate is MAGIC_BAUD it starts
 * autobaud instead of setting the UART. */
void uart_bridge_line_coding(const struct device *cdc_dev);

} // namespace probe
```
